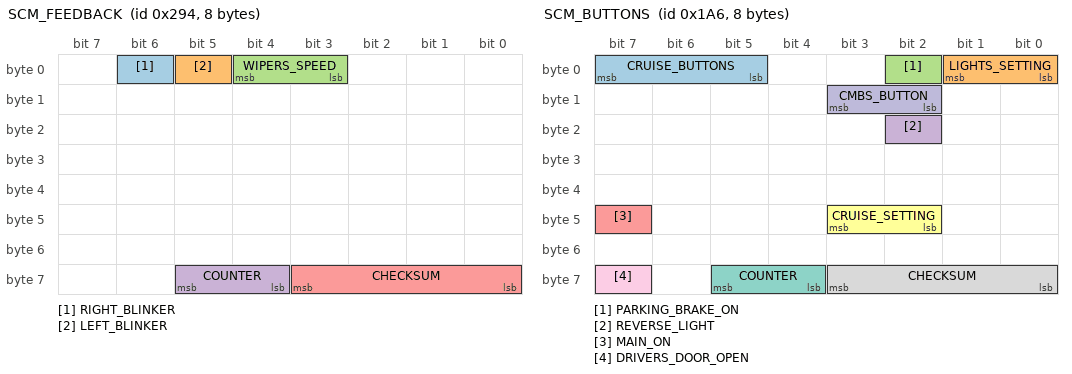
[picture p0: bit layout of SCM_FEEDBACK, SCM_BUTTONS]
BO_ 660 SCM_FEEDBACK: 8 SCM
 SG_ RIGHT_BLINKER : 6|1@0+ (1,0) [0|1] "" EON
 SG_ LEFT_BLINKER : 5|1@0+ (1,0) [0|1] "" EON
 SG_ WIPERS_SPEED : 4|2@0+ (1,0) [0|3] "" EON
 SG_ COUNTER : 61|2@0+ (1,0) [0|3] "" EON
 SG_ CHECKSUM : 59|4@0+ (1,0) [0|15] "" EON

BO_ 422 SCM_BUTTONS: 8 SCM
 SG_ CRUISE_BUTTONS : 7|3@0+ (1,0) [0|7] "" EON
 SG_ LIGHTS_SETTING : 1|2@0+ (1,0) [0|3] "" EON
 SG_ PARKING_BRAKE_ON : 2|1@0+ (1,0) [0|1] "" EON
 SG_ REVERSE_LIGHT : 18|1@0+ (1,0) [0|1] "" XXX
 SG_ MAIN_ON : 47|1@0+ (1,0) [0|1] "" EON
 SG_ CRUISE_SETTING : 43|2@0+ (1,0) [0|3] "" EON
 SG_ COUNTER : 61|2@0+ (1,0) [0|3] "" EON
 SG_ CHECKSUM : 59|4@0+ (1,0) [0|15] "" EON
 SG_ DRIVERS_DOOR_OPEN : 63|1@0+ (1,0) [0|1] "" EON
 SG_ CMBS_BUTTON : 11|2@0+ (1,0) [0|3] "" EON

VAL_ 422 CRUISE_BUTTONS 7 "tbd" 6 "tbd" 5 "tbd" 4 "accel_res" 3 "decel_set" 2 "cancel" 1 "main" 0 "none" ;
VAL_ 422 LIGHTS_SETTING 3 "high_beam" 2 "low_beam" 1 "position" 0 "no_lights" ;
VAL_ 422 CRUISE_SETTING 3 "distance_adj" 2 "tbd" 1 "lkas_button" 0 "none" ;
VAL_ 422 CMBS_BUTTON 3 "button_press" 2 "far_distance" 1 "near_distance" 0 "normal" ;
CM_ SG_ 422 CMBS_BUTTON "FCW/CMBS proximity-warning distance selector: 0 normal, 1 near, 2 far; 3 = physical button press";
